# CTRL_MMR0_CFG0 register map
Vendor: Texas Instruments
Registers are 32-bit, access per field, reset 0x8210007 unless marked. A register's access mark holds for its fields unless they carry their own. Offsets are as the file gives them; [hi:lo] are bit positions; {n}, {i} and the like mark numbered series; 'fields as' and 'values as' point back to an identical list.

## CTRL_MMR0_CFG0 (part 2 of 2)
0x4880 CTRLMMR_CCTBR_TRB0_W0 rw reset 0x8008000 — Software writable USB xHCI Transfer Request Block (TRB) 0 word0 for the Compute Cluster trace buffer transfer descriptor (TD). There are three TRBs in each TD. Each TRB consists of 4 consecutive 32-bit words (W[3:0]) defining the buffer address, buffer size and other control, as per the xHCI definition.See Trace Export via USB for more information about the trace over USB feature.
  [31:0] TRB_W0 — xHCI TRB 0 Word0
{0x4884+0x10*i} CTRLMMR_CCTBR_TRB{i}_W1 rw reset 0x0 (i=0..2) — Software writable USB xHCI Transfer Request Block (TRB) {i} word1 for the Compute Cluster trace buffer transfer descriptor (TD). There are three TRBs in each TD. Each TRB consists of 4 consecutive 32-bit words (W[3:0]) defining the buffer address, buffer size and other control, as per the xHCI definition.See Trace Export via USB for more information about the trace over USB feature.
  [31:0] TRB_W1 — xHCI TRB {i} Word1
0x4888 CTRLMMR_CCTBR_TRB0_W2 rw reset 0x1000 — Software writable USB xHCI Transfer Request Block (TRB) 0 word2 for the Compute Cluster trace buffer transfer descriptor (TD). There are three TRBs in each TD. Each TRB consists of 4 consecutive 32-bit words (W[3:0]) defining the buffer address, buffer size and other control, as per the xHCI definition.See Trace Export via USB for more information about the trace over USB feature.
  [31:0] TRB_W2 — xHCI TRB 0 Word2
0x488C CTRLMMR_CCTBR_TRB0_W3 rw reset 0x11 — Software writable USB xHCI Transfer Request Block (TRB) 0 word3 for the Compute Cluster trace buffer transfer descriptor (TD). There are three TRBs in each TD. Each TRB consists of 4 consecutive 32-bit words (W[3:0]) defining the buffer address, buffer size and other control, as per the xHCI definition.See Trace Export via USB for more information about the trace over USB feature.
  [31:0] TRB_W3 — xHCI TRB 0 Word3
0x4890 CTRLMMR_CCTBR_TRB1_W0 rw reset 0x8008000 — Software writable USB xHCI Transfer Request Block (TRB) 1 word0 for the Compute Cluster trace buffer transfer descriptor (TD). There are three TRBs in each TD. Each TRB consists of 4 consecutive 32-bit words (W[3:0]) defining the buffer address, buffer size and other control, as per the xHCI definition.See Trace Export via USB for more information about the trace over USB feature.
  [31:0] TRB_W0 — xHCI TRB 1 Word0
0x4898 CTRLMMR_CCTBR_TRB1_W2 rw reset 0x1000 — Software writable USB xHCI Transfer Request Block (TRB) 1 word2 for the Compute Cluster trace buffer transfer descriptor (TD). There are three TRBs in each TD. Each TRB consists of 4 consecutive 32-bit words (W[3:0]) defining the buffer address, buffer size and other control, as per the xHCI definition.See Trace Export via USB for more information about the trace over USB feature.
  [31:0] TRB_W2 — xHCI TRB 1 Word2
0x489C CTRLMMR_CCTBR_TRB1_W3 rw reset 0x11 — Software writable USB xHCI Transfer Request Block (TRB) 1 word3 for the Compute Cluster trace buffer transfer descriptor (TD). There are three TRBs in each TD. Each TRB consists of 4 consecutive 32-bit words (W[3:0]) defining the buffer address, buffer size and other control, as per the xHCI definition.See Trace Export via USB for more information about the trace over USB feature.
  [31:0] TRB_W3 — xHCI TRB 1 Word3
0x48A0 CTRLMMR_CCTBR_TRB2_W0 rw reset 0x1048C0 — Software writable USB xHCI Transfer Request Block (TRB) 2 word0 for the Compute Cluster trace buffer transfer descriptor (TD). There are three TRBs in each TD. Each TRB consists of 4 consecutive 32-bit words (W[3:0]) defining the buffer address, buffer size and other control, as per the xHCI definition.See Trace Export via USB for more information about the trace over USB feature.
  [31:0] TRB_W0 — xHCI TRB 2 Word0
0x48A8 CTRLMMR_CCTBR_TRB2_W2 rw reset 0x0 — Software writable USB xHCI Transfer Request Block (TRB) 2 word2 for the Compute Cluster trace buffer transfer descriptor (TD). There are three TRBs in each TD. Each TRB consists of 4 consecutive 32-bit words (W[3:0]) defining the buffer address, buffer size and other control, as per the xHCI definition.See Trace Export via USB for more information about the trace over USB feature.
  [31:0] TRB_W2 — xHCI TRB 2 Word2
0x48AC CTRLMMR_CCTBR_TRB2_W3 rw reset 0x81 — Software writable USB xHCI Transfer Request Block (TRB) 2 word3 for the Compute Cluster trace buffer transfer descriptor (TD). There are three TRBs in each TD. Each TRB consists of 4 consecutive 32-bit words (W[3:0]) defining the buffer address, buffer size and other control, as per the xHCI definition.See Trace Export via USB for more information about the trace over USB feature.
  [31:0] TRB_W3 — xHCI TRB 2 Word3
{0x48C0+4i} CTRLMMR_CCTBR_SHDW_TRB0_W{i} ro reset not defined (i=0..3) — xHC readable USB xHCI Transfer Request Block (TRB) 0 word{i} for the Compute Cluster trace buffer transfer descriptor (TD). Reflects the value contained in the corresponding CTRLMMR_CCTBR_TRB0_W{i} register. Writes to this registers are silently ignored (no error generated) allowing the xHC to continuously use the descriptor without software intervention to re-initialize the TRBs.See Trace Export via USB for more information about the trace over USB feature.
  [31:0] TRB_W{i} — xHCI TRB 0 Word{i}
{0x48D0+4i} CTRLMMR_CCTBR_SHDW_TRB1_W{i} ro reset not defined (i=0..3) — xHC readable USB xHCI Transfer Request Block (TRB) 1 word{i} for the Compute Cluster trace buffer transfer descriptor (TD). Reflects the value contained in the corresponding CTRLMMR_CCTBR_TRB1_W{i} register. Writes to this registers are silently ignored (no error generated) allowing the xHC to continuously use the descriptor without software intervention to re-initialize the TRBs.See Trace Export via USB for more information about the trace over USB feature.
  [31:0] TRB_W{i} — xHCI TRB 1 Word{i}
{0x48E0+4i} CTRLMMR_CCTBR_SHDW_TRB2_W{i} ro reset not defined (i=0..3) — xHC readable USB xHCI Transfer Request Block (TRB) 2 word{i} for the Compute Cluster trace buffer transfer descriptor (TD). Reflects the value contained in the corresponding CTRLMMR_CCTBR_TRB2_W{i} register. Writes to this registers are silently ignored (no error generated) allowing the xHC to continuously use the descriptor without software intervention to re-initialize the TRBs.See Trace Export via USB for more information about the trace over USB feature.
  [31:0] TRB_W{i} — xHCI TRB 2 Word{i}
0x4900 CTRLMMR_MCUTBR_TRB0_W0 rw reset 0x8000000 — Software writable USB xHCI Transfer Request Block (TRB) 0 word0 for the MCU trace buffer transfer descriptor (TD). There are three TRBs in each TD. Each TRB consists of 4 consecutive 32-bit words (W[3:0]) defining the buffer address, buffer size and other control, as per the xHCI definition.See Trace Export via USB for more information about the trace over USB feature.
  [31:0] TRB_W0 — xHCI TRB 0 Word0
{0x4904+0x10*i} CTRLMMR_MCUTBR_TRB{i}_W1 rw reset 0x0 (i=0..2) — Software writable USB xHCI Transfer Request Block (TRB) {i} word1 for the MCU trace buffer transfer descriptor (TD). There are three TRBs in each TD. Each TRB consists of 4 consecutive 32-bit words (W[3:0]) defining the buffer address, buffer size and other control, as per the xHCI definition.See Trace Export via USB for more information about the trace over USB feature.
  [31:0] TRB_W1 — xHCI TRB {i} Word1
0x4908 CTRLMMR_MCUTBR_TRB0_W2 rw reset 0x1000 — Software writable USB xHCI Transfer Request Block (TRB) 0 word2 for the MCU trace buffer transfer descriptor (TD). There are three TRBs in each TD. Each TRB consists of 4 consecutive 32-bit words (W[3:0]) defining the buffer address, buffer size and other control, as per the xHCI definition.See Trace Export via USB for more information about the trace over USB feature.
  [31:0] TRB_W2 — xHCI TRB 0 Word2
0x490C CTRLMMR_MCUTBR_TRB0_W3 rw reset 0x11 — Software writable USB xHCI Transfer Request Block (TRB) 0 word3 for the MCU trace buffer transfer descriptor (TD). There are three TRBs in each TD. Each TRB consists of 4 consecutive 32-bit words (W[3:0]) defining the buffer address, buffer size and other control, as per the xHCI definition.See Trace Export via USB for more information about the trace over USB feature.
  [31:0] TRB_W3 — xHCI TRB 0 Word3
0x4910 CTRLMMR_MCUTBR_TRB1_W0 rw reset 0x8000000 — Software writable USB xHCI Transfer Request Block (TRB) 1 word0 for the MCU trace buffer transfer descriptor (TD). There are three TRBs in each TD. Each TRB consists of 4 consecutive 32-bit words (W[3:0]) defining the buffer address, buffer size and other control, as per the xHCI definition.See Trace Export via USB for more information about the trace over USB feature.
  [31:0] TRB_W0 — xHCI TRB 1 Word0
0x4918 CTRLMMR_MCUTBR_TRB1_W2 rw reset 0x1000 — Software writable USB xHCI Transfer Request Block (TRB) 1 word2 for the MCU trace buffer transfer descriptor (TD). There are three TRBs in each TD. Each TRB consists of 4 consecutive 32-bit words (W[3:0]) defining the buffer address, buffer size and other control, as per the xHCI definition.See Trace Export via USB for more information about the trace over USB feature.
  [31:0] TRB_W2 — xHCI TRB 1 Word2
0x491C CTRLMMR_MCUTBR_TRB1_W3 rw reset 0x11 — Software writable USB xHCI Transfer Request Block (TRB) 1 word3 for the MCU trace buffer transfer descriptor (TD). There are three TRBs in each TD. Each TRB consists of 4 consecutive 32-bit words (W[3:0]) defining the buffer address, buffer size and other control, as per the xHCI definition.See Trace Export via USB for more information about the trace over USB feature.
  [31:0] TRB_W3 — xHCI TRB 1 Word3
0x4920 CTRLMMR_MCUTBR_TRB2_W0 rw reset 0x104940 — Software writable USB xHCI Transfer Request Block (TRB) 2 word0 for the MCU trace buffer transfer descriptor (TD). There are three TRBs in each TD. Each TRB consists of 4 consecutive 32-bit words (W[3:0]) defining the buffer address, buffer size and other control, as per the xHCI definition.See Trace Export via USB for more information about the trace over USB feature.
  [31:0] TRB_W0 — xHCI TRB 2 Word0
0x4928 CTRLMMR_MCUTBR_TRB2_W2 rw reset 0x0 — Software writable USB xHCI Transfer Request Block (TRB) 2 word2 for the MCU trace buffer transfer descriptor (TD). There are three TRBs in each TD. Each TRB consists of 4 consecutive 32-bit words (W[3:0]) defining the buffer address, buffer size and other control, as per the xHCI definition.See Trace Export via USB for more information about the trace over USB feature.
  [31:0] TRB_W2 — xHCI TRB 2 Word2
0x492C CTRLMMR_MCUTBR_TRB2_W3 rw reset 0x81 — Software writable USB xHCI Transfer Request Block (TRB) 2 word3 for the MCU trace buffer transfer descriptor (TD). There are three TRBs in each TD. Each TRB consists of 4 consecutive 32-bit words (W[3:0]) defining the buffer address, buffer size and other control, as per the xHCI definition.See Trace Export via USB for more information about the trace over USB feature.
  [31:0] TRB_W3 — xHCI TRB 2 Word3
{0x4940+4i} CTRLMMR_MCUTBR_SHDW_TRB0_W{i} ro reset not defined (i=0..3) — xHC readable USB xHCI Transfer Request Block (TRB) 0 word{i} for the MCU trace buffer transfer descriptor (TD). Register reflects the value contained in its corresponding CTRLMMR_MCUTBR_TRB0_W{i} register. Writes to this registers are silently ignored (no error generated) allowing the xHC to continuously use the descriptor without software intervention to re-initialize the TRBs.See Trace Export via USB for more information about the trace over USB feature.
  [31:0] TRB_W{i} — xHCI TRB 0 Word{i}
{0x4950+4i} CTRLMMR_MCUTBR_SHDW_TRB1_W{i} ro reset not defined (i=0..3) — xHC readable USB xHCI Transfer Request Block (TRB) 1 word{i} for the MCU trace buffer transfer descriptor (TD). Register reflects the value contained in its corresponding CTRLMMR_MCUTBR_TRB1_W{i} register. Writes to this registers are silently ignored (no error generated) allowing the xHC to continuously use the descriptor without software intervention to re-initialize the TRBs.See Trace Export via USB for more information about the trace over USB feature.
  [31:0] TRB_W{i} — xHCI TRB 1 Word{i}
{0x4960+4i} CTRLMMR_MCUTBR_SHDW_TRB2_W{i} ro reset not defined (i=0..3) — xHC readable USB xHCI Transfer Request Block (TRB) 2 word{i} for the MCU trace buffer transfer descriptor (TD). Register reflects the value contained in its corresponding CTRLMMR_MCUTBR_TRB2_W{i} register. Writes to this registers are silently ignored (no error generated) allowing the xHC to continuously use the descriptor without software intervention to re-initialize the TRBs.See Trace Export via USB for more information about the trace over USB feature.
  [31:0] TRB_W{i} — xHCI TRB 2 Word{i}
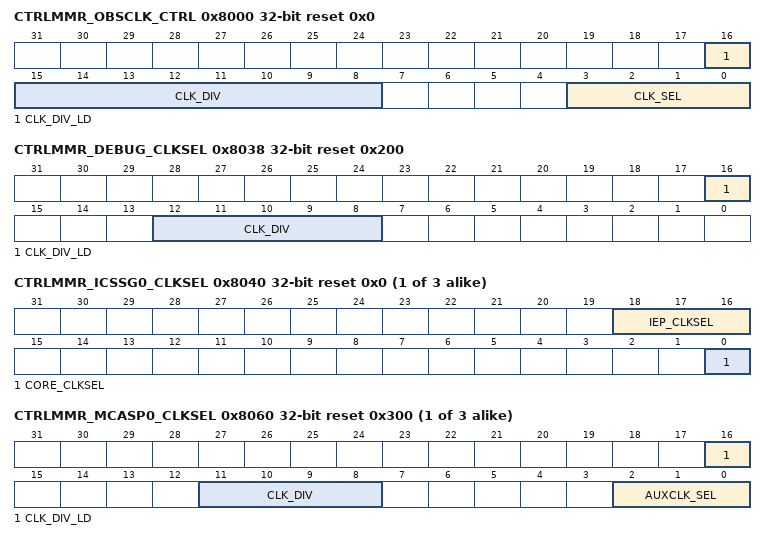
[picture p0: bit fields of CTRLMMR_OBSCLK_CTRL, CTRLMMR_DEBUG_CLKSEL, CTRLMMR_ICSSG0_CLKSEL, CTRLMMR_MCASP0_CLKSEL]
0x8000 CTRLMMR_OBSCLK_CTRL reset 0x0 — This register controls which internal clock is made observable on the OBSCLK output pin.
  [16] CLK_DIV_LD rw — Load the output divider value
  [15:8] CLK_DIV rw — OBSCLK pin output divider
  [3:0] CLK_SEL rw — OBSCLK pin output clock source selection 0h - HFOSC1_CLK 1h - HFOSC0_CLK 2h - MAIN_PLL 3h - PER0_PLL 4h - LFOSC_CLKOUT 5h - PER1_PLL 6h - DSS_PLL 7h - ARM0_PLL 8h - DDR_PLL 9h - CPSW_PLL Ah - PLLCTRL_OBSCLK Bh - ARM1_PLL Ch - cpts_genf2 Dh - cpts_genf3 Eh - cpts_genf4 Fh - cpts_genf5
0x8020 CTRLMMR_SERDES0_REFCLK_SEL reset 0x0 — Selects the source of the SERDES0 reference clock.
  [1:0] CLK_SEL rw — SERDES0 Internal REFCLK source select mux control 0h - HFOSC0_CLK 1h - HFOSC1_OUT 2h - MAIN_PLL_CLKOUT 3h - MAINHSDIV_CLKOUT4
0x8024 CTRLMMR_SERDES1_REFCLK_SEL reset 0x0 — Selects the source of the SERDES1 reference clock.
  [1:0] CLK_SEL rw — SERDES1 Internal REFCLK source select mux control 0h - HFOSC0_CLK 1h - HFOSC1_OUT 2h - MAIN_PLL_CLKOUT 3h - MAINHSDIV_CLKOUT4
0x8030 CTRLMMR_GTC_CLKSEL reset 0x0 — Selects the timebase clock source for the Global Timebase Counter.
  [2:0] CLK_SEL rw — Selects the GTC timebase clock source 0h - CPSWHSDIV_CLKOUT2 1h - MAINHSDIV_CLKOUT3 2h - MCU_CPTS_REF_CLK (pin) 3h - CPTS_RFT_CLK (pin) 4h - MCU_EXT_REFCLK0 (pin) 5h - EXT_REFCLK1 (pin) 6h - PCIE0_TXI0_CLK 7h - PCIE1_TXI0_CLK
0x8038 CTRLMMR_DEBUG_CLKSEL reset 0x200 — Selects the Debug trace clock source.
  [16] CLK_DIV_LD rw — Load the output divider value
  [12:8] CLK_DIV rw — Selects the programmable divider value for the trace clock source for the Debug Subsystem. The clock frequency is PER0_PLL_CLKOUT / (clk_div+1) Supports divide values of 1 to 32 Default is /3. To load the new divider value the clk_div_ld bit must be cleared and then set to 1.
0x803C CTRLMMR_EFUSE_CLKSEL reset 0x0 — Selects the functional clock source for the MAIN domain eFuse Controller.
  [0] CLK_SEL rw — Selects the clock source 0h - EFUSE_CLK (from WKUP_PRC) 1h - MAIN_SYSCLK0 / 4
{0x8040+4i} CTRLMMR_ICSSG{i}_CLKSEL reset 0x0 (i=0..2) — Selects the functional clock source for ICSS-G{i}.
  [18:16] IEP_CLKSEL rw — Selects the ICSSG{i} IEP clock source 0h - CPSWHSDIV_CLKOUT2 1h - MAINHSDIV_CLKOUT3 2h - MCU_CPTS_REF_CLK (pin) 3h - CPTS_RFT_CLK (pin) 4h - MCU_EXT_REFCLK0 (pin) 5h - EXT_REFCLK1 (pin) 6h - PCIE0_TXI0_CLK 7h - PCIE1_TXI0_CLK
  [0] CORE_CLKSEL rw — Selects the ICSSG{i} functional clock source 0h - PER1HSDIV_CLKOUT1 1h - CPSWHSDIV_CLKOUT2
{0x8060+4i} CTRLMMR_MCASP{i}_CLKSEL reset 0x300 (i=0..2) — Selects the functional clock source for McASP{i}.
  [16] CLK_DIV_LD rw — Load the output divider value
  [11:8] CLK_DIV rw — Selects the programmable divider value for the ARM1_PLL_CLKOUT clock source for McASP{i} The clock frequency is ARM1_PLL_CLKOUT / (clk_div+1) Supports divide values of 1 to 16 Default is /4. To load the new divider value the clk_div_ld bit must be cleared and then set to 1.
  [2:0] AUXCLK_SEL rw — Selects the McASP{i} auxclk clock source Reserved values default to HFOSC1_CLK 0h - HFOSC1_CLK 1h - HFOSC0_CLK 2h - MCU_EXT_REFCLK0 3h - PER1HSDIV_CLKOUT2 4h - Divided ARM1_PLL_CLKOUT (see clkdiv) 5h - EXT_REFCLK1 6h - reserved (HFOSC1_CLK) 7h - reserved (HFOSC1_CLK)
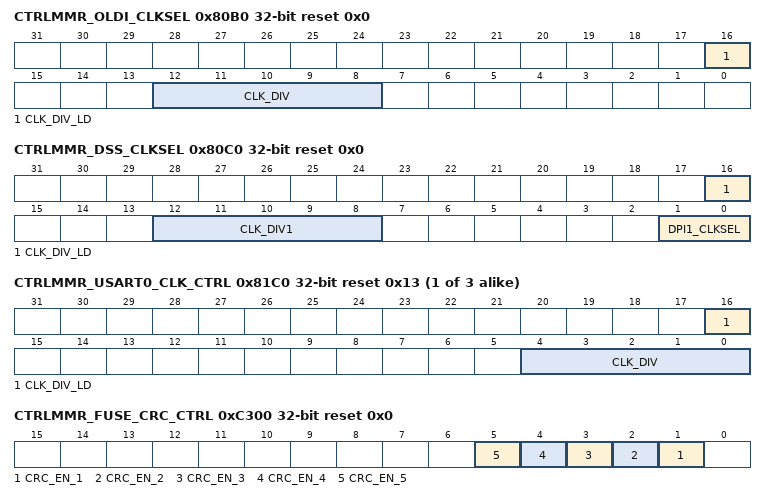
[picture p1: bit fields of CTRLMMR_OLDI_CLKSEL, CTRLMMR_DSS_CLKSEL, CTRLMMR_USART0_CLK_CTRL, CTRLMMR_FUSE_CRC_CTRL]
0x80B0 CTRLMMR_OLDI_CLKSEL reset 0x0 — Selects the functional clock source for OLDI.
  [16] CLK_DIV_LD rw — Load the output divider value
  [12:8] CLK_DIV rw — Selects the programmable divide value for the OLDI PLL input.
0x80C0 CTRLMMR_DSS_CLKSEL reset 0x0 — Selects DSS clock sources.
  [16] CLK_DIV_LD rw — Load the output divider value
  [12:8] CLK_DIV1 rw — Selects the programmable divide value for the DSS DPI_1_IN_CLK mux input. The clock frequency is DSS_PLL_CLKOUT / (clk_div1+1) Supports divide values of 1 (default) to 32. To load the new divider value the clk_div_ld bit must be cleared and then set to 1.
  [1:0] DPI1_CLKSEL rw — Selects the clock source for DPI1 (parallel output) 0h - DPI_0_IN_CLK 1h - DSS0EXTPCLKIN (pin) 2h - Divided DSS_PLL_CLKOUT (see clk_div1) 3h - 0'
0x80D0 CTRLMMR_GPMC_CLKSEL reset 0x0 — Selects the bus and functional clock source for the GPMC module. This allows the GPMC to run asynchronously to the bus fabric in order to optimize parallel port performance.
  [1:0] CLK_SEL rw — Selects the GPMC clock source
0x80E0 CTRLMMR_USB0_CLKSEL reset 0x0 — Selects the functional clock sources for USB0.
  [0] REFCLK_SEL rw — Selects the clock source for the USB0 ref_clk.
0x80E4 CTRLMMR_USB1_CLKSEL reset 0x0 — Selects the functional clock sources for USB1.
  [0] REFCLK_SEL rw — Selects the clock source for the USB1 ref_clk.
{0x8100+4i} CTRLMMR_TIMER{i}_CLKSEL reset 0x0 (i=0..11) — Timer{i} functional clock selection control.
  [3:0] CLK_SEL rw — Timer functional clock input select mux control (Reserved values default to HFOSC1_CLK) 0h - HFOSC0_CLK 1h - HFOSC1_CLK 2h - MAINHSDIV_CLKOUT3 3h - CLK_12M_RC 4h - CPSWHSDIV_CLKOUT2 5h - MCU_EXT_REFCLK0 6h - EXT_REFCLK1 7h - LFOSC_CLKOUT 8h - CPTS_RFT_CLK (pin) 9h - PER1HSDIV_CLKOUT2 Ah - PER0_PLL_CLKOUT_DIV5 Bh - CLK_32K_RC Ch - CPTS_GENF2 Dh - CPTS_GENF3 Eh - CPTS_GENF4 Fh - CPTS_GENF5
{0x81C0+4i} CTRLMMR_USART{i}_CLK_CTRL reset 0x13 (i=0..2) — Selects the clock divider of the USART{i} functional clock.
  [16] CLK_DIV_LD rw — Load the output divider value
  [4:0] CLK_DIV rw — Selects the clock divider value. Supports divide values of 1 to 32 Default is /4. To load the new divider value the clk_div_ld bit must be cleared and then set to 1. 0h - Divide by 1 1h - Divide by 2 2h - Divide by 3 3h - Divide by 4 4h - Divide by 5 5h - Divide by 6 6h - Divide by 7 7h - Divide by 8 8h - Divide by 9 9h - Divide by 10 Ah - Divide by 11 Bh - Divide by 12 Ch - Divide by 13 Dh - Divide by 14 Eh - Divide by 15 Fh - Divide by 16 10h - Divide by 17 11h - Divide by 18 12h - Divide by 19 13h - Divide by 20 14h - Divide by 21 15h - Divide by 22 16h - Divide by 23 17h - Divide by 24 18h - Divide by 25 19h - Divide by 26 1Ah - Divide by 27 1Bh - Divide by 28 1Ch - Divide by 29 1Dh - Divide by 30 1Eh - Divide by 31 1Fh - Divide by 32
0xC300 CTRLMMR_FUSE_CRC_CTRL reset 0x0 — Controls MAIN efuse chain CRC calculation.
  [n] CRC_EN_{n} rw (n=1..5) — Enable eFuse CRC calculation for chain {n}
{0xC300+4i} CTRLMMR_CHAIN{i}_CRC_FUSE ro reset not defined (i=1..5) — Indicates the stored CRC for MAIN fuse chain {i}.
  [31:0] CRC — Stored chain CRC
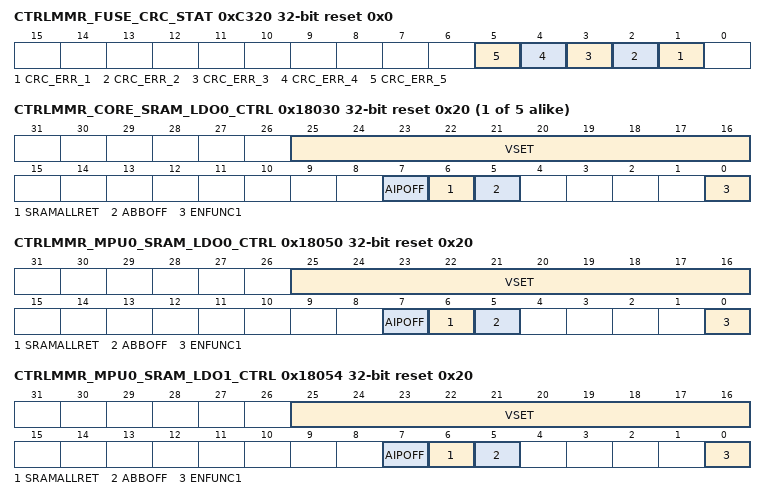
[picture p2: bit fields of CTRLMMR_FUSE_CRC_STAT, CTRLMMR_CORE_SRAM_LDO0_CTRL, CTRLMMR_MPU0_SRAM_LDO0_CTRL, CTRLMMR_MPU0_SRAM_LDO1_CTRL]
0xC320 CTRLMMR_FUSE_CRC_STAT ro reset 0x0 (reset mask 0xFFFFFFC1) — Indicates status of fuse chain CRC.
  [n] CRC_ERR_{n} (n=1..5) — Indicates eFuse CRC error on chain {n}
{0xC320+4i} CTRLMMR_CHAIN{i}_CRC_CALC ro reset not defined (i=1..5) — Indicates the calculated CRC for MAIN fuse chain {i}.
  [31:0] CRC — Calculated chain CRC
{0x18030+4i} CTRLMMR_CORE_SRAM_LDO{i}_CTRL reset 0x20 (reset mask 0xFC00FFFF) (i=0..4) — Controls operation of the MAIN Core VD SRAM LDO{i} module.
  [25:16] VSET rw — LDO trim bits
  [7] AIPOFF rw — When set, disables the VSLDO and enables IDDQ test mode
  [6] SRAMALLRET rw — When set, places the VSLDO in retention mode
  [5] ABBOFF rw — When set, shorts the VNWA voltage to VDDAR
  [0] ENFUNC1 rw — Control the LDO loop dynamics. Setting enfunc0 decreases loop gain by 6dB.
0x18050 CTRLMMR_MPU0_SRAM_LDO0_CTRL reset 0x20 (reset mask 0xFC00FFFF) — Controls operation of the MAIN MPU0 VD SRAM LDO0 module.
  fields as CTRLMMR_CORE_SRAM_LDO0_CTRL
0x18054 CTRLMMR_MPU0_SRAM_LDO1_CTRL reset 0x20 (reset mask 0xFC00FFFF) — Controls operation of the MAIN MPU0 VD SRAM LDO1 module.
  fields as CTRLMMR_CORE_SRAM_LDO0_CTRL
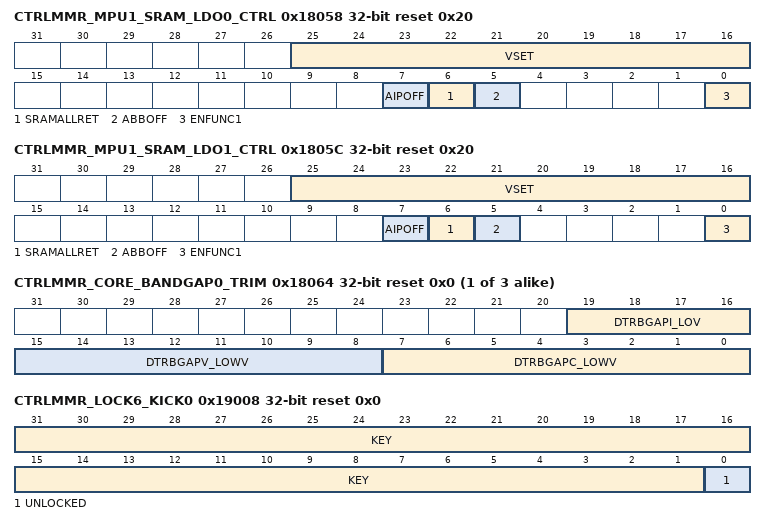
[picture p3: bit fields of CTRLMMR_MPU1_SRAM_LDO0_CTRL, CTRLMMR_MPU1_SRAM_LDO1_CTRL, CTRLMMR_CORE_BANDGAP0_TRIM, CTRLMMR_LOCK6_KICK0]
0x18058 CTRLMMR_MPU1_SRAM_LDO0_CTRL reset 0x20 (reset mask 0xFC00FFFF) — Controls operation of the MAIN MPU1 VD SRAM LDO0 module.
  fields as CTRLMMR_CORE_SRAM_LDO0_CTRL
0x1805C CTRLMMR_MPU1_SRAM_LDO1_CTRL reset 0x20 (reset mask 0xFC00FFFF) — Controls operation of the MAIN MPU1 VD SRAM LDO1 module.
  fields as CTRLMMR_CORE_SRAM_LDO0_CTRL
{0x18060+8i} CTRLMMR_CORE_BANDGAP{i}_CTRL reset 0x1 (i=0..2) — Controls operation of the MAIN Core VD Bandgap {i} Regulator.
  [0] BG_EN_LV rw — When set, bandgap regulator is on
{0x18064+8i} CTRLMMR_CORE_BANDGAP{i}_TRIM reset 0x0 (reset mask 0xFFF00000) (i=0..2) — Trims the MAIN Core VD Bandgap{i} Regulator.
  [19:16] DTRBGAPI_LOV rw — Bandgap output current trim bits
  [15:8] DTRBGAPV_LOWV rw — Bandgap output voltage magnitude trim bits
  [7:0] DTRBGAPC_LOWV rw — Bandgap slope trim bits. Bit7 is used to calculate the offset
0x19008 CTRLMMR_LOCK6_KICK0 reset 0x0 — Lower 32-bits of Partition6 write lock key. This register must be written with the designated key value followed by a write to CTRLMMR_LOCK6_KICK1 with its key value before write-protected Partition 6 registers can be written.
  [31:1] KEY rw — Write the kick0 unlock value followed by the kick1 unlock value to unlock the write-protected Partition6 registers
  [0] UNLOCKED ro — Unlock status. When set indicates that the proper umlock sequence has been performed and the partition is unlocked for writing.
0x1900C CTRLMMR_LOCK6_KICK1 rw reset 0x0 — Upper 32-bits of Partition 6 write lock key. This register must be written with the designated key value after a write to CTRLMMR_LOCK6_KICK0 with its key value before write-protected Partition 6 registers can be written.
  [31:0] KEY — Write the kick1 unlock value after the kick0 unlock value to unlock the write-protected Partition6 registers
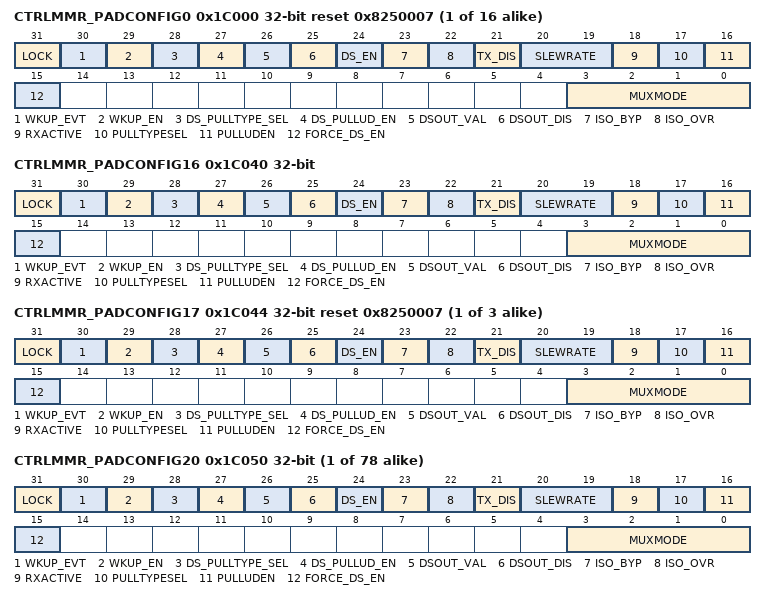
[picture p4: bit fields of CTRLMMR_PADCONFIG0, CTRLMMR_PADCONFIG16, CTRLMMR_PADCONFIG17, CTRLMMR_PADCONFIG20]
{0x1C000+4i} CTRLMMR_PADCONFIG{i} reset 0x8250007 (i=0..15) — Register to control pin configuration and muxing.
  [31] LOCK rw
  [30] WKUP_EVT ro — Wakeup event status
  [29] WKUP_EN rw — Wakeup enable
  [28] DS_PULLTYPE_SEL rw — Deep Sleep 0 mode pull-up/down selection
  [27] DS_PULLUD_EN rw — Deep Sleep 0 mode pull-up/down enable (active low)
  [26] DSOUT_VAL rw — Deep Sleep 0 mode output value
  [25] DSOUT_DIS rw — Deep Sleep 0 mode output disable
  [24] DS_EN rw — Deep Sleep 0 mode override control
  [23] ISO_BYP rw — Isolation Bypass
  [22] ISO_OVR rw — Isolation Override
  [21] TX_DIS rw — Driver Disable
  [20:19] SLEWRATE rw — Slew rate control selection (CS1, CS0) 0h - 200 MHz 1h - 150 MHz 2h - 100 MHz 3h - 50 MHz
  [18] RXACTIVE rw — Input enable for the Pad
  [17] PULLTYPESEL rw — Pad Pullup / Pulldown type selection
  [16] PULLUDEN rw — Pad Pullup / Pulldown enable. This is an active low signal.
  [15] FORCE_DS_EN rw — Enable pad Deep Sleep controls by overriding DMSC gating
  [3:0] MUXMODE rw — Pad functional signal mux selection 0h - Mux Mode 0 1h - Mux Mode 1 2h - Mux Mode 2 3h - Mux Mode 3 4h - Mux Mode 4 5h - Mux Mode 5 6h - Mux Mode 6 7h - Mux Mode 7 Fh - Mux Mode 15
0x1C040 CTRLMMR_PADCONFIG16 — Register to control pin configuration and muxing.
  fields as CTRLMMR_PADCONFIG0
{0x1C000+4i} CTRLMMR_PADCONFIG{i} reset 0x8250007 (i=17..19) — Register to control pin configuration and muxing.
  fields as CTRLMMR_PADCONFIG0
{0x1C000+4i} CTRLMMR_PADCONFIG{i} (i=20..97) — Register to control pin configuration and muxing.
  fields as CTRLMMR_PADCONFIG0
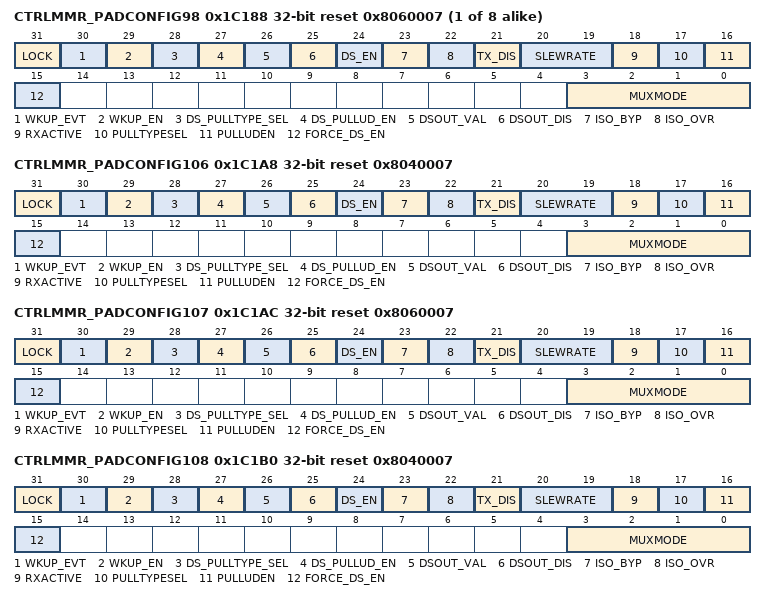
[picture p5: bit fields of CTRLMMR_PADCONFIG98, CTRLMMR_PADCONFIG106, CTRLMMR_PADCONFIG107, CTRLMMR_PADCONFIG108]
{0x1C000+4i} CTRLMMR_PADCONFIG{i} reset 0x8060007 (i=98..105) — Register to control pin configuration and muxing.
  fields as CTRLMMR_PADCONFIG0
0x1C1A8 CTRLMMR_PADCONFIG106 reset 0x8040007 — Register to control pin configuration and muxing.
  fields as CTRLMMR_PADCONFIG0
0x1C1AC CTRLMMR_PADCONFIG107 reset 0x8060007 — Register to control pin configuration and muxing.
  fields as CTRLMMR_PADCONFIG0
0x1C1B0 CTRLMMR_PADCONFIG108 reset 0x8040007 — Register to control pin configuration and muxing.
  fields as CTRLMMR_PADCONFIG0
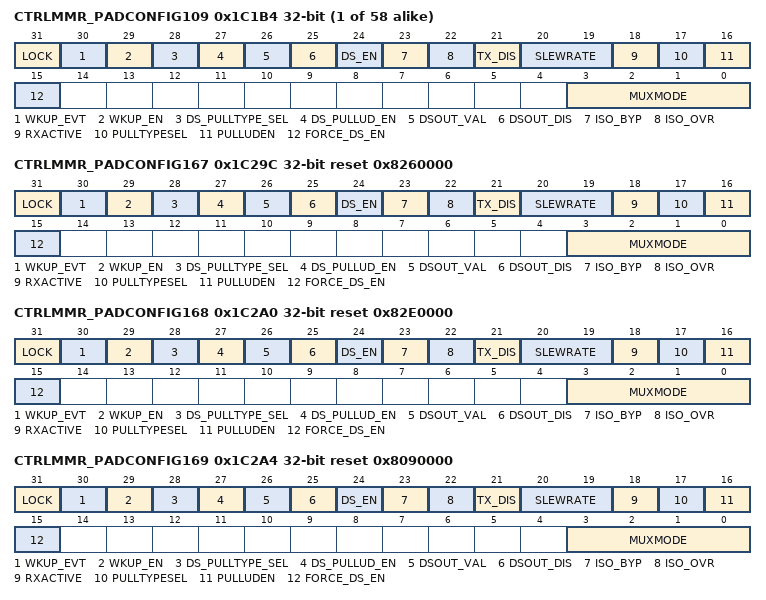
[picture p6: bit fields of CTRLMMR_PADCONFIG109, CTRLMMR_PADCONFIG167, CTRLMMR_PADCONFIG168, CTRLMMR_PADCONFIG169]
{0x1C000+4i} CTRLMMR_PADCONFIG{i} (i=109..166) — Register to control pin configuration and muxing.
  fields as CTRLMMR_PADCONFIG0
0x1C29C CTRLMMR_PADCONFIG167 reset 0x8260000 — Register to control pin configuration and muxing.
  fields as CTRLMMR_PADCONFIG0
0x1C2A0 CTRLMMR_PADCONFIG168 reset 0x82E0000 — Register to control pin configuration and muxing.
  fields as CTRLMMR_PADCONFIG0
0x1C2A4 CTRLMMR_PADCONFIG169 reset 0x8090000 — Register to control pin configuration and muxing.
  fields as CTRLMMR_PADCONFIG0
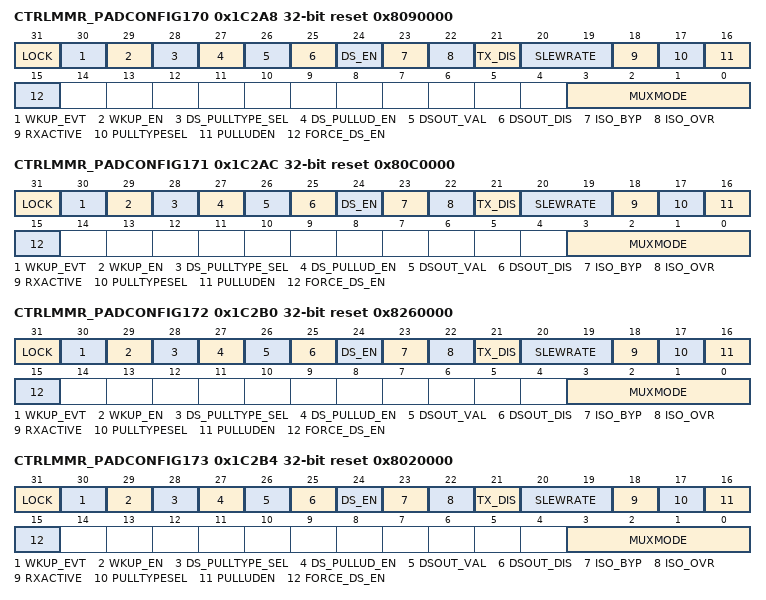
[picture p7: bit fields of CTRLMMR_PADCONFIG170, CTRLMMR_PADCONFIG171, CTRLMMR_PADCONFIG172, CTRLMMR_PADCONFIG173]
0x1C2A8 CTRLMMR_PADCONFIG170 reset 0x8090000 — Register to control pin configuration and muxing.
  fields as CTRLMMR_PADCONFIG0
0x1C2AC CTRLMMR_PADCONFIG171 reset 0x80C0000 — Register to control pin configuration and muxing.
  fields as CTRLMMR_PADCONFIG0
0x1C2B0 CTRLMMR_PADCONFIG172 reset 0x8260000 — Register to control pin configuration and muxing.
  fields as CTRLMMR_PADCONFIG0
0x1C2B4 CTRLMMR_PADCONFIG173 reset 0x8020000 — Register to control pin configuration and muxing.
  fields as CTRLMMR_PADCONFIG0
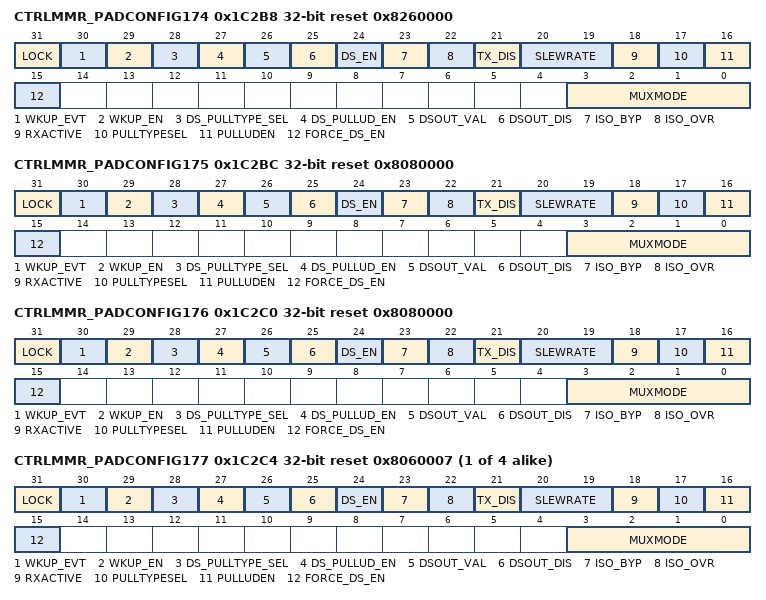
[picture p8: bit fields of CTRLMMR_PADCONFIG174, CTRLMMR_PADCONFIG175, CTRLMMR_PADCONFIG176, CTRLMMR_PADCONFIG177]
0x1C2B8 CTRLMMR_PADCONFIG174 reset 0x8260000 — Register to control pin configuration and muxing.
  fields as CTRLMMR_PADCONFIG0
0x1C2BC CTRLMMR_PADCONFIG175 reset 0x8080000 — Register to control pin configuration and muxing.
  fields as CTRLMMR_PADCONFIG0
0x1C2C0 CTRLMMR_PADCONFIG176 reset 0x8080000 — Register to control pin configuration and muxing.
  fields as CTRLMMR_PADCONFIG0
{0x1C000+4i} CTRLMMR_PADCONFIG{i} reset 0x8060007 (i=177..180) — Register to control pin configuration and muxing.
  fields as CTRLMMR_PADCONFIG0
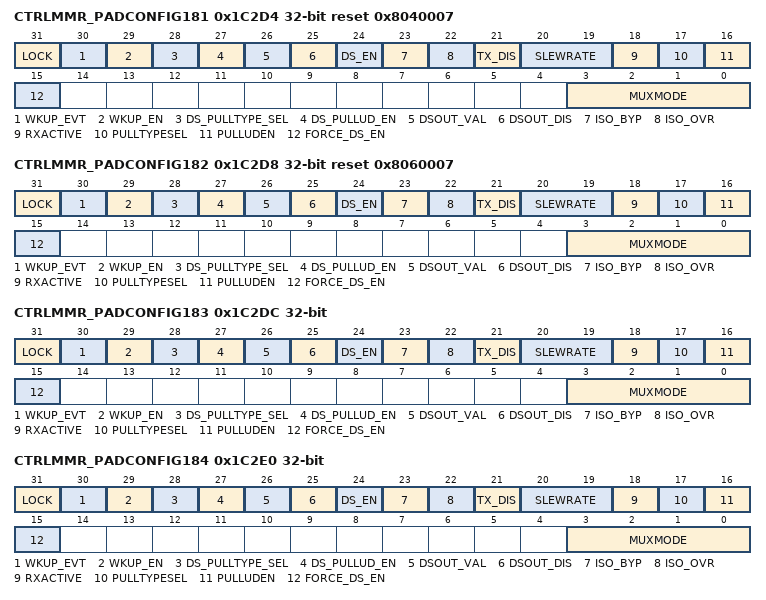
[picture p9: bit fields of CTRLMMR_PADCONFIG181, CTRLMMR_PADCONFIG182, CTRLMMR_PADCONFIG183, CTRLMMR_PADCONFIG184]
0x1C2D4 CTRLMMR_PADCONFIG181 reset 0x8040007 — Register to control pin configuration and muxing.
  fields as CTRLMMR_PADCONFIG0
0x1C2D8 CTRLMMR_PADCONFIG182 reset 0x8060007 — Register to control pin configuration and muxing.
  fields as CTRLMMR_PADCONFIG0
0x1C2DC CTRLMMR_PADCONFIG183 — Register to control pin configuration and muxing.
  fields as CTRLMMR_PADCONFIG0
0x1C2E0 CTRLMMR_PADCONFIG184 — Register to control pin configuration and muxing.
  fields as CTRLMMR_PADCONFIG0
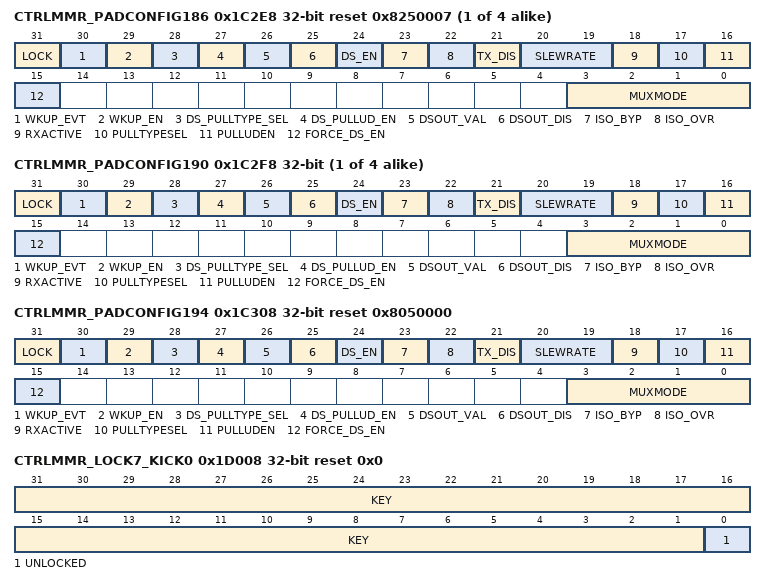
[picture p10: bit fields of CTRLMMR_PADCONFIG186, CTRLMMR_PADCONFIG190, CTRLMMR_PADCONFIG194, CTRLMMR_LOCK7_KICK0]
{0x1C000+4i} CTRLMMR_PADCONFIG{i} reset 0x8250007 (i=186..189) — Register to control pin configuration and muxing.
  fields as CTRLMMR_PADCONFIG0
{0x1C000+4i} CTRLMMR_PADCONFIG{i} (i=190..193) — Register to control pin configuration and muxing.
  fields as CTRLMMR_PADCONFIG0
0x1C308 CTRLMMR_PADCONFIG194 reset 0x8050000 — Register to control pin configuration and muxing.
  fields as CTRLMMR_PADCONFIG0
0x1D008 CTRLMMR_LOCK7_KICK0 reset 0x0 — Lower 32-bits of Partition7 write lock key. This register must be written with the designated key value followed by a write to CTRLMMR_LOCK7_KICK1 with its key value before write-protected Partition 7 registers can be written.
  [31:1] KEY rw — Write the kick0 unlock value followed by the kick1 unlock value to unlock the write-protected Partition7 registers
  [0] UNLOCKED ro — Unlock status. When set indicates that the proper unlock sequence has been performed and the partition is unlocked for writing.
0x1D00C CTRLMMR_LOCK7_KICK1 rw reset 0x0 — Upper 32-bits of Partition 7 write lock key. This register must be written with the designated key value after a write to CTRLMMR_LOCK7_KICK0 with its key value before write-protected Partition 7 registers can be written.
  [31:0] KEY — Write the kick1 unlock value after the kick0 unlock value to unlock the write-protected Partition7 registers
